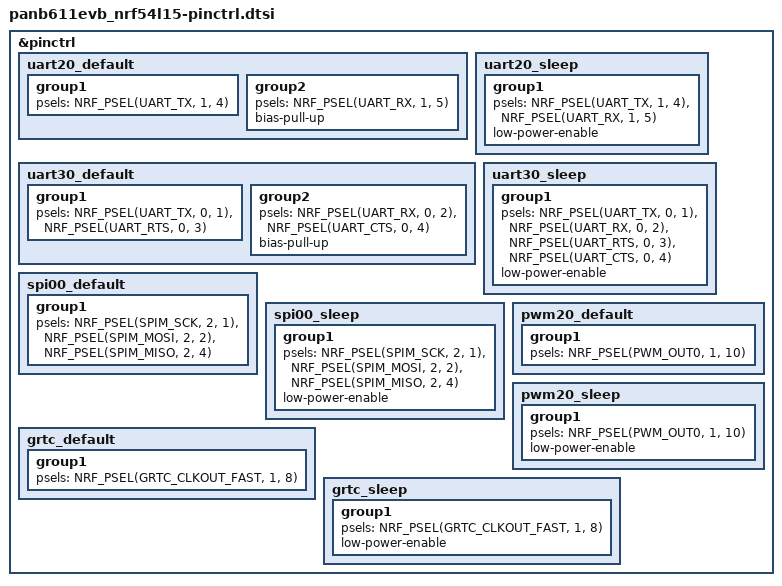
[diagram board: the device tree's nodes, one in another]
/*
 * Copyright (c) 2025 Panasonic Industrial Devices Europe GmbH
 * SPDX-License-Identifier: Apache-2.0
 */

&pinctrl {
	/omit-if-no-ref/ uart20_default: uart20_default {
		group1 {
			psels = <NRF_PSEL(UART_TX, 1, 4)>;
		};

		group2 {
			psels = <NRF_PSEL(UART_RX, 1, 5)>;
			bias-pull-up;
		};
	};

	/omit-if-no-ref/ uart20_sleep: uart20_sleep {
		group1 {
			psels = <NRF_PSEL(UART_TX, 1, 4)>,
				<NRF_PSEL(UART_RX, 1, 5)>;
			low-power-enable;
		};
	};

	/omit-if-no-ref/ uart30_default: uart30_default {
		group1 {
			psels = <NRF_PSEL(UART_TX, 0, 1)>,
				<NRF_PSEL(UART_RTS, 0, 3)>;
		};

		group2 {
			psels = <NRF_PSEL(UART_RX, 0, 2)>,
				<NRF_PSEL(UART_CTS, 0, 4)>;
			bias-pull-up;
		};
	};

	/omit-if-no-ref/ uart30_sleep: uart30_sleep {
		group1 {
			psels = <NRF_PSEL(UART_TX, 0, 1)>,
				<NRF_PSEL(UART_RX, 0, 2)>,
				<NRF_PSEL(UART_RTS, 0, 3)>,
				<NRF_PSEL(UART_CTS, 0, 4)>;
			low-power-enable;
		};
	};

	/omit-if-no-ref/ spi00_default: spi00_default {
		group1 {
			psels = <NRF_PSEL(SPIM_SCK, 2, 1)>,
				<NRF_PSEL(SPIM_MOSI, 2, 2)>,
				<NRF_PSEL(SPIM_MISO, 2, 4)>;
		};
	};

	/omit-if-no-ref/ spi00_sleep: spi00_sleep {
		group1 {
			psels = <NRF_PSEL(SPIM_SCK, 2, 1)>,
				<NRF_PSEL(SPIM_MOSI, 2, 2)>,
				<NRF_PSEL(SPIM_MISO, 2, 4)>;
			low-power-enable;
		};
	};

	/omit-if-no-ref/ pwm20_default: pwm20_default {
		group1 {
			psels = <NRF_PSEL(PWM_OUT0, 1, 10)>;
		};
	};

	/omit-if-no-ref/ pwm20_sleep: pwm20_sleep {
		group1 {
			psels = <NRF_PSEL(PWM_OUT0, 1, 10)>;
			low-power-enable;
		};
	};

	/*
	 * Note that P0.04 is the dedicated pin to output the LFCLK
	 * (32 KHz clock). Add the following line:
	 * <NRF_PSEL(GRTC_CLKOUT_32K, 0, 4)>
	 * to the grtc_default and grtc_sleep node.
	 * Note that this may will affect the uart30 (CTS) functionality.
	 */
	/omit-if-no-ref/ grtc_default: grtc_default {
		group1 {
			psels = <NRF_PSEL(GRTC_CLKOUT_FAST, 1, 8)>;
		};
	};

	/omit-if-no-ref/ grtc_sleep: grtc_sleep {
		group1 {
			psels = <NRF_PSEL(GRTC_CLKOUT_FAST, 1, 8)>;
			low-power-enable;
		};
	};
};
